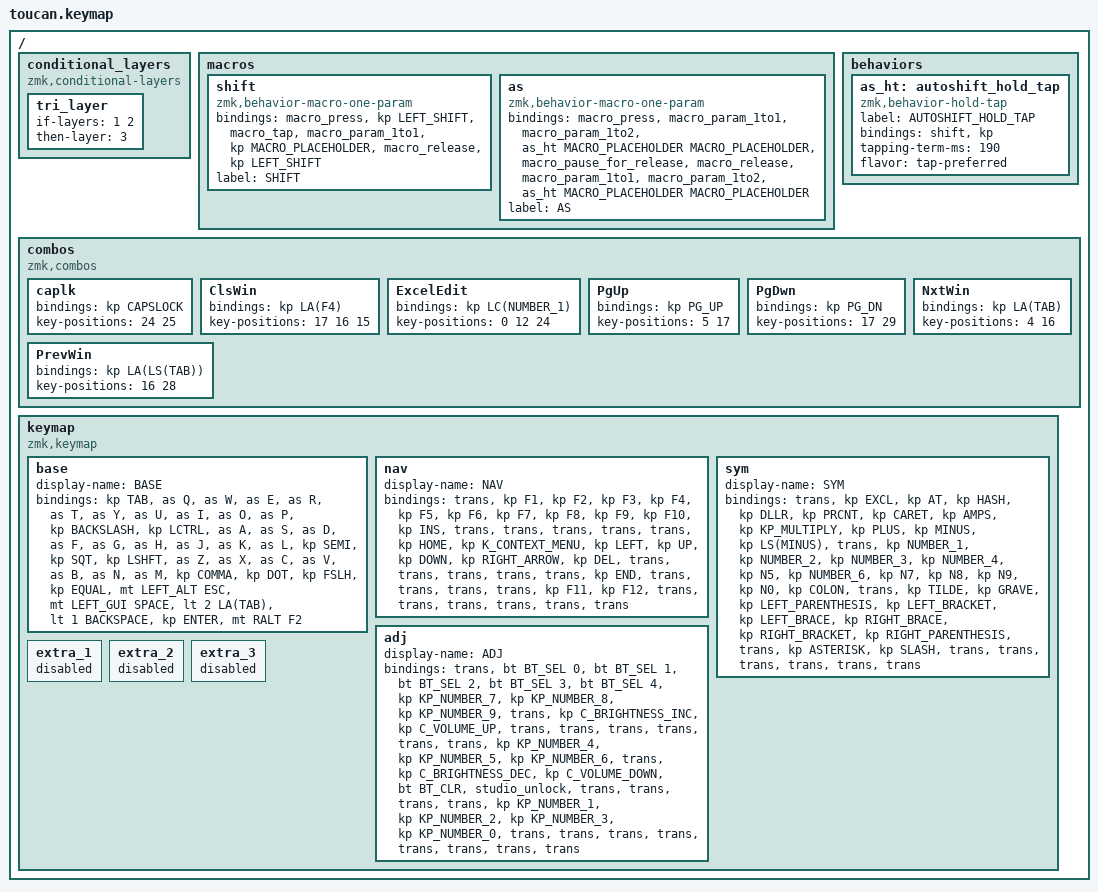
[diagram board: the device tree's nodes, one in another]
#include <behaviors.dtsi>
#include <dt-bindings/zmk/bt.h>
#include <dt-bindings/zmk/keys.h>

#define BASE 0
#define NAV  1
#define SYM  2
#define ADJ  3

/ {
    conditional_layers {
        compatible = "zmk,conditional-layers";

        tri_layer {
            if-layers = <1 2>;
            then-layer = <3>;
        };
    };

    macros {
        shift: shift {
            compatible = "zmk,behavior-macro-one-param";
            #binding-cells = <1>;
            bindings =
                <&macro_press>,
                <&kp LEFT_SHIFT>,
                <&macro_tap>,
                <&macro_param_1to1 &kp MACRO_PLACEHOLDER>,
                <&macro_release>,
                <&kp LEFT_SHIFT>;

            label = "SHIFT";
        };

        as: as {
            compatible = "zmk,behavior-macro-one-param";
            #binding-cells = <1>;
            bindings =
                <&macro_press>,
                <&macro_param_1to1 &macro_param_1to2 &as_ht MACRO_PLACEHOLDER MACRO_PLACEHOLDER>,
                <&macro_pause_for_release>,
                <&macro_release>,
                <&macro_param_1to1 &macro_param_1to2 &as_ht MACRO_PLACEHOLDER MACRO_PLACEHOLDER>;

            label = "AS";
        };
    };

    behaviors {
        as_ht: autoshift_hold_tap {
            compatible = "zmk,behavior-hold-tap";
            label = "AUTOSHIFT_HOLD_TAP";
            bindings = <&shift>, <&kp>;

            #binding-cells = <2>;
            tapping-term-ms = <190>;
            flavor = "tap-preferred";
        };
    };

    combos {
        compatible = "zmk,combos";

        caplk {
            bindings = <&kp CAPSLOCK>;
            key-positions = <24 25>;
        };

        ClsWin {
            bindings = <&kp LA(F4)>;
            key-positions = <17 16 15>;
        };

        ExcelEdit {
            bindings = <&kp LC(NUMBER_1)>;
            key-positions = <0 12 24>;
        };

        PgUp {
            bindings = <&kp PG_UP>;
            key-positions = <5 17>;
        };

        PgDwn {
            bindings = <&kp PG_DN>;
            key-positions = <17 29>;
        };

        NxtWin {
            bindings = <&kp LA(TAB)>;
            key-positions = <4 16>;
        };

        PrevWin {
            bindings = <&kp LA(LS(TAB))>;
            key-positions = <16 28>;
        };
    };

    keymap {
        compatible = "zmk,keymap";

        base {
            display-name = "BASE";
            bindings = <
&kp TAB  &as Q  &as W  &as E  &as R  &as T  &as Y  &as U  &as I  &as O  &as P  &kp BACKSLASH  &kp LCTRL  &as A  &as S  &as D  &as F  &as G  &as H  &as J  &as K  &as L  &kp SEMI  &kp SQT  &kp LSHFT  &as Z  &as X  &as C  &as V  &as B  &as N  &as M  &kp COMMA  &kp DOT  &kp FSLH  &kp EQUAL  &mt LEFT_ALT ESC  &mt LEFT_GUI SPACE  &lt 2 LA(TAB)  &lt 1 BACKSPACE  &kp ENTER  &mt RALT F2
            >;
        };

        nav {
            display-name = "NAV";
            bindings = <
&trans  &kp F1  &kp F2  &kp F3  &kp F4  &kp F5  &kp F6  &kp F7  &kp F8  &kp F9  &kp F10  &kp INS  &trans  &trans  &trans  &trans  &trans  &kp HOME  &kp K_CONTEXT_MENU  &kp LEFT  &kp UP  &kp DOWN  &kp RIGHT_ARROW  &kp DEL  &trans  &trans  &trans  &trans  &trans  &kp END  &trans  &trans  &trans  &trans  &kp F11  &kp F12  &trans  &trans  &trans  &trans  &trans  &trans
            >;
        };

        sym {
            display-name = "SYM";
            bindings = <
&trans  &kp EXCL  &kp AT  &kp HASH  &kp DLLR  &kp PRCNT  &kp CARET  &kp AMPS  &kp KP_MULTIPLY  &kp PLUS  &kp MINUS  &kp LS(MINUS)  &trans  &kp NUMBER_1  &kp NUMBER_2  &kp NUMBER_3  &kp NUMBER_4  &kp N5  &kp NUMBER_6  &kp N7  &kp N8  &kp N9  &kp N0  &kp COLON  &trans  &kp TILDE  &kp GRAVE  &kp LEFT_PARENTHESIS  &kp LEFT_BRACKET  &kp LEFT_BRACE  &kp RIGHT_BRACE  &kp RIGHT_BRACKET  &kp RIGHT_PARENTHESIS  &trans  &kp ASTERISK  &kp SLASH  &trans  &trans  &trans  &trans  &trans  &trans
            >;
        };

        adj {
            display-name = "ADJ";
            bindings = <
&trans  &bt BT_SEL 0  &bt BT_SEL 1  &bt BT_SEL 2  &bt BT_SEL 3  &bt BT_SEL 4  &kp KP_NUMBER_7  &kp KP_NUMBER_8  &kp KP_NUMBER_9  &trans  &kp C_BRIGHTNESS_INC  &kp C_VOLUME_UP  &trans  &trans  &trans  &trans  &trans  &trans  &kp KP_NUMBER_4  &kp KP_NUMBER_5  &kp KP_NUMBER_6  &trans  &kp C_BRIGHTNESS_DEC  &kp C_VOLUME_DOWN  &bt BT_CLR  &studio_unlock  &trans  &trans  &trans  &trans  &kp KP_NUMBER_1  &kp KP_NUMBER_2  &kp KP_NUMBER_3  &kp KP_NUMBER_0  &trans  &trans  &trans  &trans  &trans  &trans  &trans  &trans
            >;
        };

        extra_1 { status = "reserved"; };

        extra_2 { status = "reserved"; };

        extra_3 { status = "reserved"; };
    };
};
